VERSION "l77rodeo_gmlan_starter_2026-09-29"

NS_ :

BS_:

BU_: ECM TCM GW UNKNOWN

BO_ 199 GMLAN_0C7: 8 UNKNOWN

BO_ 241 GMLAN_0F1: 4 UNKNOWN

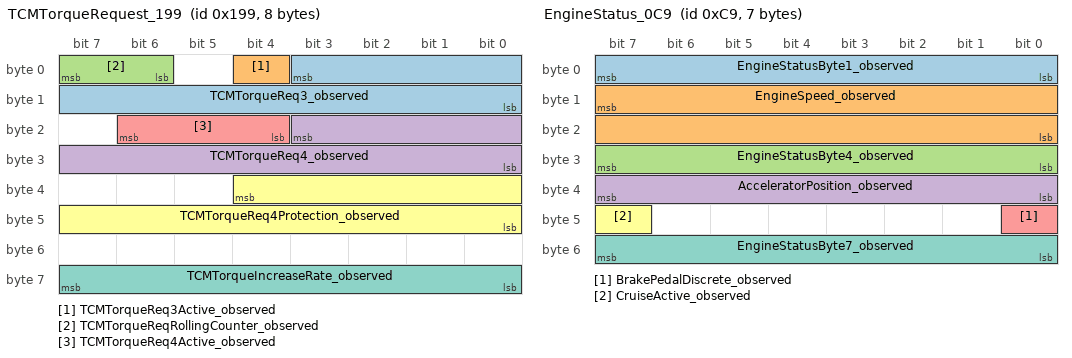
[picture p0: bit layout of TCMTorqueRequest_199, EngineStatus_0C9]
BO_ 409 TCMTorqueRequest_199: 8 TCM
 SG_ TCMTorqueReq3_observed : 3|12@0+ (0.5,-848) [-848|1199.5] "Nm" TCM
 SG_ TCMTorqueReq3Active_observed : 4|1@0+ (1,0) [0|1] "" TCM
 SG_ TCMTorqueReqRollingCounter_observed : 6|2@1+ (1,0) [0|3] "" TCM
 SG_ TCMTorqueReq4_observed : 19|12@0+ (0.5,-848) [-848|1199.5] "Nm" TCM
 SG_ TCMTorqueReq4Active_observed : 22|3@0+ (1,0) [0|7] "" TCM
 SG_ TCMTorqueReq4Protection_observed : 36|13@0+ (1,0) [0|8191] "" TCM
 SG_ TCMTorqueIncreaseRate_observed : 63|8@0+ (1,0) [0|255] "" TCM

BO_ 201 EngineStatus_0C9: 7 UNKNOWN
 SG_ EngineStatusByte1_observed : 0|8@1+ (1,0) [0|255] "" UNKNOWN
 SG_ EngineSpeed_observed : 15|16@0+ (0.25,0) [0|16383.75] "rpm" UNKNOWN
 SG_ EngineStatusByte4_observed : 24|8@1+ (1,0) [0|255] "" UNKNOWN
 SG_ AcceleratorPosition_observed : 32|8@1+ (0.3921568627,0) [0|100] "%" UNKNOWN
 SG_ BrakePedalDiscrete_observed : 40|1@1+ (1,0) [0|1] "" UNKNOWN
 SG_ CruiseActive_observed : 47|1@1+ (1,0) [0|1] "" UNKNOWN
 SG_ EngineStatusByte7_observed : 48|8@1+ (1,0) [0|255] "" UNKNOWN

BO_ 495 GMLAN_1EF: 8 UNKNOWN

BO_ 401 GMLAN_191: 8 UNKNOWN

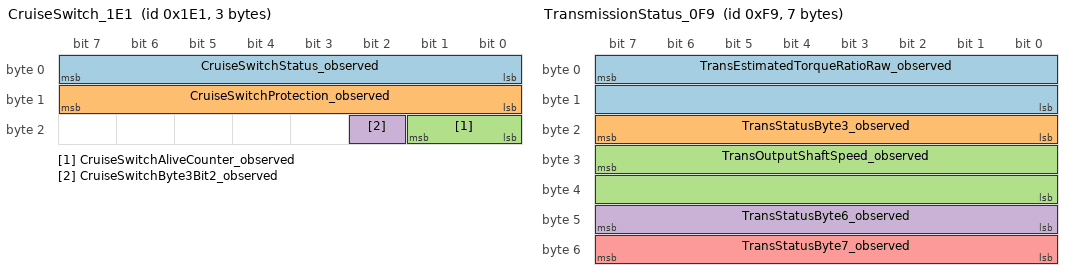
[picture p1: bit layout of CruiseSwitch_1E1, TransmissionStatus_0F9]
BO_ 481 CruiseSwitch_1E1: 3 UNKNOWN
 SG_ CruiseSwitchStatus_observed : 0|8@1+ (1,0) [0|255] "" UNKNOWN
 SG_ CruiseSwitchProtection_observed : 8|8@1+ (1,0) [0|255] "" UNKNOWN
 SG_ CruiseSwitchAliveCounter_observed : 16|2@1+ (1,0) [0|3] "" UNKNOWN
 SG_ CruiseSwitchByte3Bit2_observed : 18|1@1+ (1,0) [0|1] "" UNKNOWN

BO_ 505 GMLAN_1F9: 8 UNKNOWN

BO_ 413 GMLAN_19D: 8 UNKNOWN

BO_ 249 TransmissionStatus_0F9: 7 UNKNOWN
 SG_ TransEstimatedTorqueRatioRaw_observed : 7|16@0+ (1,0) [0|65535] "raw" UNKNOWN
 SG_ TransStatusByte3_observed : 16|8@1+ (1,0) [0|255] "" UNKNOWN
 SG_ TransOutputShaftSpeed_observed : 31|16@0+ (0.25,0) [0|16383.75] "rpm" UNKNOWN
 SG_ TransStatusByte6_observed : 40|8@1+ (1,0) [0|255] "" UNKNOWN
 SG_ TransStatusByte7_observed : 48|8@1+ (1,0) [0|255] "" UNKNOWN

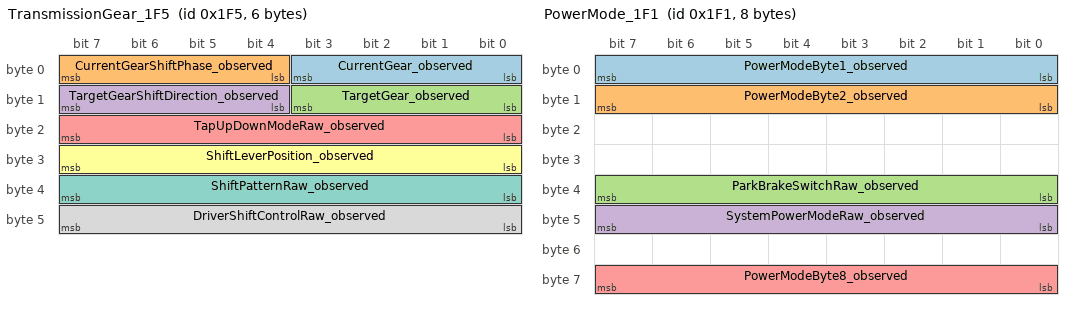
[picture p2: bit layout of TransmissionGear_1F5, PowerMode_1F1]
BO_ 501 TransmissionGear_1F5: 6 UNKNOWN
 SG_ CurrentGear_observed : 0|4@1+ (1,0) [0|15] "" UNKNOWN
 SG_ CurrentGearShiftPhase_observed : 4|4@1+ (1,0) [0|15] "" UNKNOWN
 SG_ TargetGear_observed : 8|4@1+ (1,0) [0|15] "" UNKNOWN
 SG_ TargetGearShiftDirection_observed : 12|4@1+ (1,0) [0|15] "" UNKNOWN
 SG_ TapUpDownModeRaw_observed : 16|8@1+ (1,0) [0|255] "" UNKNOWN
 SG_ ShiftLeverPosition_observed : 24|8@1+ (1,0) [0|255] "" UNKNOWN
 SG_ ShiftPatternRaw_observed : 32|8@1+ (1,0) [0|255] "" UNKNOWN
 SG_ DriverShiftControlRaw_observed : 40|8@1+ (1,0) [0|255] "" UNKNOWN

BO_ 499 TransmissionSwitches_1F3: 8 UNKNOWN

BO_ 493 GMLAN_1ED: 8 UNKNOWN

BO_ 393 GMLAN_189: 8 UNKNOWN

BO_ 904 GMLAN_388: 8 UNKNOWN

BO_ 431 GMLAN_1AF: 8 UNKNOWN

BO_ 896 GMLAN_380: 8 UNKNOWN

BO_ 969 GMLAN_3C9: 8 UNKNOWN

BO_ 640 GMLAN_280: 8 UNKNOWN

BO_ 298 GMLAN_12A: 8 UNKNOWN

BO_ 721 GMLAN_2D1: 8 UNKNOWN

BO_ 451 GMLAN_1C3: 8 UNKNOWN

BO_ 497 PowerMode_1F1: 8 UNKNOWN
 SG_ PowerModeByte1_observed : 0|8@1+ (1,0) [0|255] "" UNKNOWN
 SG_ PowerModeByte2_observed : 8|8@1+ (1,0) [0|255] "" UNKNOWN
 SG_ ParkBrakeSwitchRaw_observed : 32|8@1+ (1,0) [0|255] "" UNKNOWN
 SG_ SystemPowerModeRaw_observed : 40|8@1+ (1,0) [0|255] "" UNKNOWN
 SG_ PowerModeByte8_observed : 56|8@1+ (1,0) [0|255] "" UNKNOWN

BO_ 417 GMLAN_1A1: 3 UNKNOWN

BO_ 707 GMLAN_2C3: 8 UNKNOWN

BO_ 1217 GMLAN_4C1: 8 UNKNOWN

BO_ 1001 GMLAN_3E9: 8 UNKNOWN

BO_ 752 GMLAN_2F0: 8 UNKNOWN

BO_ 1009 GMLAN_3F1: 6 UNKNOWN

BO_ 1019 GMLAN_3FB: 8 UNKNOWN

BO_ 961 GMLAN_3C1: 8 UNKNOWN

BO_ 1017 GMLAN_3F9: 8 UNKNOWN

BO_ 977 GMLAN_3D1: 8 UNKNOWN

BO_ 1905 GMLAN_771: 7 UNKNOWN

BO_ 1233 GMLAN_4D1: 8 UNKNOWN

BO_ 1225 GMLAN_4C9: 4 UNKNOWN

BO_ 1249 GMLAN_4E1: 8 UNKNOWN

BO_ 1300 GMLAN_514: 8 UNKNOWN

BO_ 312 GMLAN_138: 5 UNKNOWN

BO_ 304 GMLAN_130: 8 UNKNOWN

BO_ 1257 PlatformConfig_4E9: 2 UNKNOWN

BO_ 1322 GMLAN_52A: 8 UNKNOWN

BO_ 1919 GMLAN_77F: 7 UNKNOWN

BO_ 1906 GMLAN_772: 7 UNKNOWN

BO_ 1649 GMLAN_671: 8 UNKNOWN

BO_ 288 GMLAN_120: 5 UNKNOWN

BO_ 1601 GMLAN_641: 8 UNKNOWN

BO_ 1265 GMLAN_4F1: 6 UNKNOWN

BO_ 577 GMLAN_241: 8 UNKNOWN

BO_ 580 GMLAN_244: 8 UNKNOWN

BO_ 1604 GMLAN_644: 8 UNKNOWN

BO_ 1348 GMLAN_544: 8 UNKNOWN

BO_ 193 Observed_0C1: 8 UNKNOWN

BO_ 197 Observed_0C5: 8 UNKNOWN

BO_ 381 Observed_17D: 8 UNKNOWN

BO_ 383 Observed_17F: 8 UNKNOWN

BO_ 388 Observed_184: 1 UNKNOWN

BO_ 449 Observed_1C1: 4 UNKNOWN

BO_ 457 Observed_1C9: 7 UNKNOWN

BO_ 461 Observed_1CD: 5 UNKNOWN

BO_ 485 Observed_1E5: 8 UNKNOWN

BO_ 489 Observed_1E9: 8 UNKNOWN

BO_ 523 Observed_20B: 8 UNKNOWN

BO_ 535 Observed_217: 8 UNKNOWN

BO_ 587 Observed_24B: 8 UNKNOWN

BO_ 592 Observed_250: 8 UNKNOWN

BO_ 599 Observed_257: 8 UNKNOWN

BO_ 659 Observed_293: 8 UNKNOWN

BO_ 660 Observed_294: 8 UNKNOWN

BO_ 667 Observed_29B: 8 UNKNOWN

BO_ 678 Observed_2A6: 8 UNKNOWN

BO_ 709 Observed_2C5: 6 UNKNOWN

BO_ 712 Observed_2C8: 8 UNKNOWN

BO_ 715 Observed_2CB: 8 UNKNOWN

BO_ 761 Observed_2F9: 5 UNKNOWN

BO_ 786 Observed_312: 8 UNKNOWN

BO_ 804 Observed_324: 6 UNKNOWN

BO_ 823 Observed_337: 8 UNKNOWN

BO_ 838 Observed_346: 8 UNKNOWN

BO_ 840 Observed_348: 4 UNKNOWN

BO_ 842 Observed_34A: 4 UNKNOWN

BO_ 848 Observed_350: 8 UNKNOWN

BO_ 851 Observed_353: 8 UNKNOWN

BO_ 888 Observed_378: 8 UNKNOWN

BO_ 919 Observed_397: 8 UNKNOWN

BO_ 920 Observed_398: 8 UNKNOWN

BO_ 922 Observed_39A: 8 UNKNOWN

BO_ 953 Observed_3B9: 8 UNKNOWN

BO_ 975 Observed_3CF: 8 UNKNOWN

BO_ 979 Observed_3D3: 8 UNKNOWN

BO_ 984 Observed_3D8: 8 UNKNOWN

BO_ 1003 Observed_3EB: 8 UNKNOWN

BO_ 1011 Observed_3F3: 8 UNKNOWN

BO_ 1024 Observed_400: 8 UNKNOWN

BO_ 1026 Observed_402: 8 UNKNOWN

BO_ 1029 Observed_405: 8 UNKNOWN

BO_ 1031 Observed_407: 8 UNKNOWN

BO_ 1058 Observed_422: 8 UNKNOWN

BO_ 1079 Observed_437: 8 UNKNOWN

BO_ 1111 Observed_457: 8 UNKNOWN

BO_ 1117 Observed_45D: 8 UNKNOWN

BO_ 1141 Observed_475: 8 UNKNOWN

BO_ 1143 Observed_477: 8 UNKNOWN

BO_ 1149 Observed_47D: 8 UNKNOWN

BO_ 1197 Observed_4AD: 8 UNKNOWN

BO_ 1210 Observed_4BA: 8 UNKNOWN

BO_ 1216 Observed_4C0: 8 UNKNOWN

BO_ 1244 Observed_4DC: 8 UNKNOWN

BO_ 1264 Observed_4F0: 8 UNKNOWN

BO_ 1266 Observed_4F2: 8 UNKNOWN

BO_ 1268 Observed_4F4: 8 UNKNOWN

BO_ 1271 Observed_4F7: 8 UNKNOWN

BO_ 1272 Observed_4F8: 8 UNKNOWN

BO_ 1274 Observed_4FA: 8 UNKNOWN

BO_ 1275 Observed_4FB: 8 UNKNOWN

BO_ 1276 Observed_4FC: 8 UNKNOWN

BO_ 1277 Observed_4FD: 8 UNKNOWN

BO_ 1278 Observed_4FE: 8 UNKNOWN

BO_ 1279 Observed_4FF: 8 UNKNOWN

BO_ 1281 Observed_501: 8 UNKNOWN

BO_ 1297 Observed_511: 8 UNKNOWN

BO_ 1310 Observed_51E: 8 UNKNOWN

BO_ 1316 Observed_524: 8 UNKNOWN

BO_ 1320 Observed_528: 5 UNKNOWN

BO_ 1343 Observed_53F: 8 UNKNOWN

BO_ 1907 Observed_773: 7 UNKNOWN

BO_ 1918 Observed_77E: 7 UNKNOWN

CM_ "DBC expanded from the l77rodeo/GMLAN starter plus this repo's 2007 GM captures. Signals suffixed _observed are decoded from local CSV/video-task correlation; use comments for confidence and remaining validation needs.";
CM_ BO_ 201 "Repository-listed contents: Accelerator actual position; Accelerator actual position validity; Engine run active; Engine speed; Engine speed status; Platform engine speed command inhibit request; Power takeoff powertrain run aborted; Powertrain brake pedal discrete input; Powertrain brake pedal discrete input validity; Powertrain crank aborted; Powertrain crank active; Powertrain run aborted; Remote vehicle start engine running; Cylinder deactivation mode; Engine idle active; Driver throttle override detected; Cruise control enabled; Cruise control active status.";
CM_ BO_ 249 "Repository-listed contents: Transmission output shaft angular velocity; Transmission output shaft angular velocity sensor present; Transmission output shaft angular velocity validity; Transmission overall estimated torque ratio; Transmission overall estimated torque ratio validity.";
CM_ BO_ 499 "Repository-listed contents: Overdrive disable requested; Platform transmission tap up/tap down enable switch state; Platform transmission tap up/tap down switch state; Platform transmission tap up/tap down switch status rolling count; Transmission oil life reset request; Transmission platform shift pattern switches 1-4 active; Transmission platform shift pattern switch alive rolling count.";
CM_ BO_ 501 "Repository-listed contents: Automatic transmission commanded gear; Automatic transmission gear shift direction; Driver shift control request denied indicator on; Driver shift control target gear; Engine recommended upshift indicator on; Overdrive disable granted; Top of travel clutch switch active/validity; Transmission creep mode active; Transmission estimated gear/validity; Transmission range inhibit status; Transmission shift lever lock requested; Transmission shift lever position/validity; Transmission shift mode status; Transmission shift pattern active status; Transmission skip shift indicator on; Transmission tap up/tap down mode status.";
CM_ BO_ 481 "Repository-listed contents: Cruise control cancel request; Cruise control switch status; Cruise control switch status alive rolling count; Cruise control switch status protection value.";
CM_ BO_ 497 "Repository-listed contents: Display measurement system; Engine oil life reset request; Immobilizer pre-release password/status; Park brake switch active; Park brake virtual device availability; Power mode master accessory; Power mode master run/crank terminal status; PTO/remote-start master engine shutdown/start requests; Remote vehicle start request; System backup power mode/enabled; System power mode; Throttle progression request.";
CM_ BO_ 1257 "Repository-listed contents: A/C compressor type; Elapsed time count/reset; ABS present; Platform engine speed command system type; Traction control system present; Vehicle speed control system type; Vehicle stability enhancement system present.";

CM_ SG_ 201 EngineSpeed_observed "High confidence. Bytes D2-D3 big-endian scaled by 0.25 rpm: warm idle decodes about 580-660 rpm; rpm-500-inc reaches about 3200 rpm; WOT reaches about 5500 rpm.";
CM_ SG_ 201 AcceleratorPosition_observed "High confidence. D5 scales 0-100%; idle/brake/AC remain 0, normal accel peaks near 29%, throttle blips near 70%, WOT near 100%.";
CM_ SG_ 201 BrakePedalDiscrete_observed "Observed from brake-pedal timing. D6 is 0x40 when released and 0x41 near spoken Brake on events; bit0 is the brake-pedal discrete.";
CM_ SG_ 201 CruiseActive_observed "Inferred. D6 bit7 appears only during portions of cruise.csv where the drive task should have cruise active; confirm exact semantics from video.";
CM_ SG_ 409 TCMTorqueReq3_observed "Provisional but strong. Community layout for TCM->ECM torque request on 0x199; idle/brake inactive value is 1199.5 Nm with active=0, and Req3 drops/active=1 during upshift torque-management windows.";
CM_ SG_ 409 TCMTorqueReq3Active_observed "Provisional. Active bit rises during many 0x1F5 upshift target windows. Treat as the primary torque-reduction active flag for this capture set.";
CM_ SG_ 409 TCMTorqueReqRollingCounter_observed "Observed rolling counter cycles 0..3; U0101 diagnostics reportedly monitor rolling counts on 0x199/0x19D.";
CM_ SG_ 409 TCMTorqueReq4_observed "Provisional. Mostly inactive 625 Nm in these captures; appears during some manual downshift/rev-match style windows.";
CM_ SG_ 409 TCMTorqueReq4Protection_observed "Provisional protection/check value. Tracks counter/request as expected by community decode; do not transmit arbitrary values without generating protection correctly.";
CM_ SG_ 249 TransEstimatedTorqueRatioRaw_observed "Observed raw field. D1-D2 big-endian follows transmission gear/ratio state, not output speed: examples include 0x07AF in 1st/drive stationary, 0x00AA in 6th, 0x7CF0 in reverse, and 0x0000 in park/neutral.";
CM_ SG_ 249 TransOutputShaftSpeed_observed "High confidence. D4-D5 big-endian scales as 0.25 rpm/count for transmission output shaft speed. User observation: raw value near 6000 is about 40 mph, which is consistent with about 1500 rpm output speed before final drive/tire conversion.";
CM_ SG_ 501 CurrentGear_observed "High confidence. Low nibble of D1 is the current/achieved gear during drive captures. Example upshift sequence: 01 12 -> 02 12 -> 02 02.";
CM_ SG_ 501 CurrentGearShiftPhase_observed "Observed shift-phase nibble in high nibble of D1. 0=steady, 2 and 4 appear during in-progress shifts and likely mark shift/torque-management phases.";
CM_ SG_ 501 TargetGear_observed "High confidence. Low nibble of D2 is the target/next gear during shifts; equals current gear when stable.";
CM_ SG_ 501 TargetGearShiftDirection_observed "High confidence direction nibble in high nibble of D2. 0=steady, 1=upshift target, 2=downshift target.";
CM_ SG_ 501 ShiftLeverPosition_observed "High confidence selector/manual gear byte from PRNDL task: Park=1, Reverse=2, Neutral=3, Drive/M6=4, M5=5, M4=6, M3=7, M2=8, M1=9.";
CM_ SG_ 501 TapUpDownModeRaw_observed "Inferred. D3 is 0x10 during manual/tap mode sections and 0x00 in normal PRNDL/park captures.";
CM_ SG_ 501 DriverShiftControlRaw_observed "Inferred. D6 is 0x02 during manual/tap mode sections and 0x00 in normal PRNDL/park captures.";
CM_ SG_ 481 CruiseSwitchStatus_observed "Confirmed by user/video review. 0x00=cruise off, 0x40=cruise on/no buttons, 0x54=negative/set button down, 0x68=plus/resume button down, 0xC0=cancel button down.";
CM_ SG_ 481 CruiseSwitchProtection_observed "Protection/check byte. Verified against cruise_timeline and raw 0x1E1 frames: Protection = (-CruiseSwitchStatus - (D3 & 0x03)) & 0xFF. Examples released 0x40 gives C0/BF/BE/BD for counter 0/1/2/3.";
CM_ SG_ 481 CruiseSwitchAliveCounter_observed "Low two bits of D3. Cycles 0..3 and is included in the cruise switch protection formula. D3 is not a full 0..255 counter.";
CM_ SG_ 481 CruiseSwitchByte3Bit2_observed "D3 bit2. Set in key-on-key-off-cold and parts of cold-start when status is 0x00, producing D3 values 0x04..0x07. Not included in protection calculation.";
CM_ SG_ 497 SystemPowerModeRaw_observed "Raw observed power-mode byte. Mostly 0x10 run, with 0x11/0x12 seen during PRNDL/key-state transitions; exact enum needs key-state video review.";

VAL_ 501 ShiftLeverPosition_observed 1 "Park" 2 "Reverse" 3 "Neutral" 4 "Drive/M6" 5 "M5" 6 "M4" 7 "M3" 8 "M2" 9 "M1";
VAL_ 501 TargetGearShiftDirection_observed 0 "Steady" 1 "Upshift_Target" 2 "Downshift_Target";
VAL_ 501 CurrentGearShiftPhase_observed 0 "Steady" 2 "ShiftPhase_A_observed" 4 "ShiftPhase_B_observed";
VAL_ 481 CruiseSwitchStatus_observed 0 "Cruise_Off" 64 "Cruise_On_NoButtons" 84 "Negative_Set_Button" 104 "Plus_Resume_Button" 192 "Cancel_Button";
